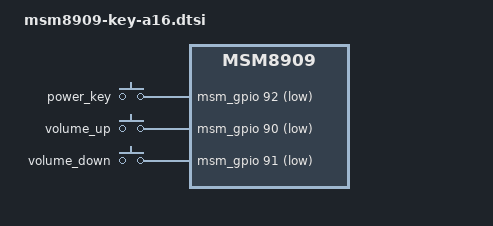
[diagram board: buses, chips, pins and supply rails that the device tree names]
&soc{
	gpio_keys {
		compatible = "gpio-keys";
		input-name = "gpio-keys";

		power_key {
			label = "power_key";
			gpios = <&msm_gpio 92 0x1>;
			linux,input-type = <1>;
			linux,code = <116>;
			gpio-key,wakeup;
			debounce-interval = <20>;
		};

		vol_up {
			label = "volume_up";
			gpios = <&msm_gpio 90 0x1>;
			linux,input-type = <1>;
			linux,code = <115>;
			debounce-interval = <20>;
		};

		vol_down {
			label = "volume_down";
			gpios = <&msm_gpio 91 0x1>;
			linux,input-type = <1>;
			linux,code = <114>;
			debounce-interval = <20>;
		};
	};

	tlmm_pinmux: pinctrl@1000000 {
		tlmm_gpio_key {
			qcom,pins = <&gp 90>, <&gp 91>, <&gp 92>;
			qcom,pin-func = <0>;
			qcom,num-grp-pins = <3>;
			label = "tlmm_gpio_key";
			gpio_key_active: gpio_key_active {
				drive-strength = <2>;
				bias-pull-up;
			};
			gpio_key_suspend: gpio_key_suspend {
				drive-strength = <2>;
				bias-pull-up;
			};
		};
	};
};
